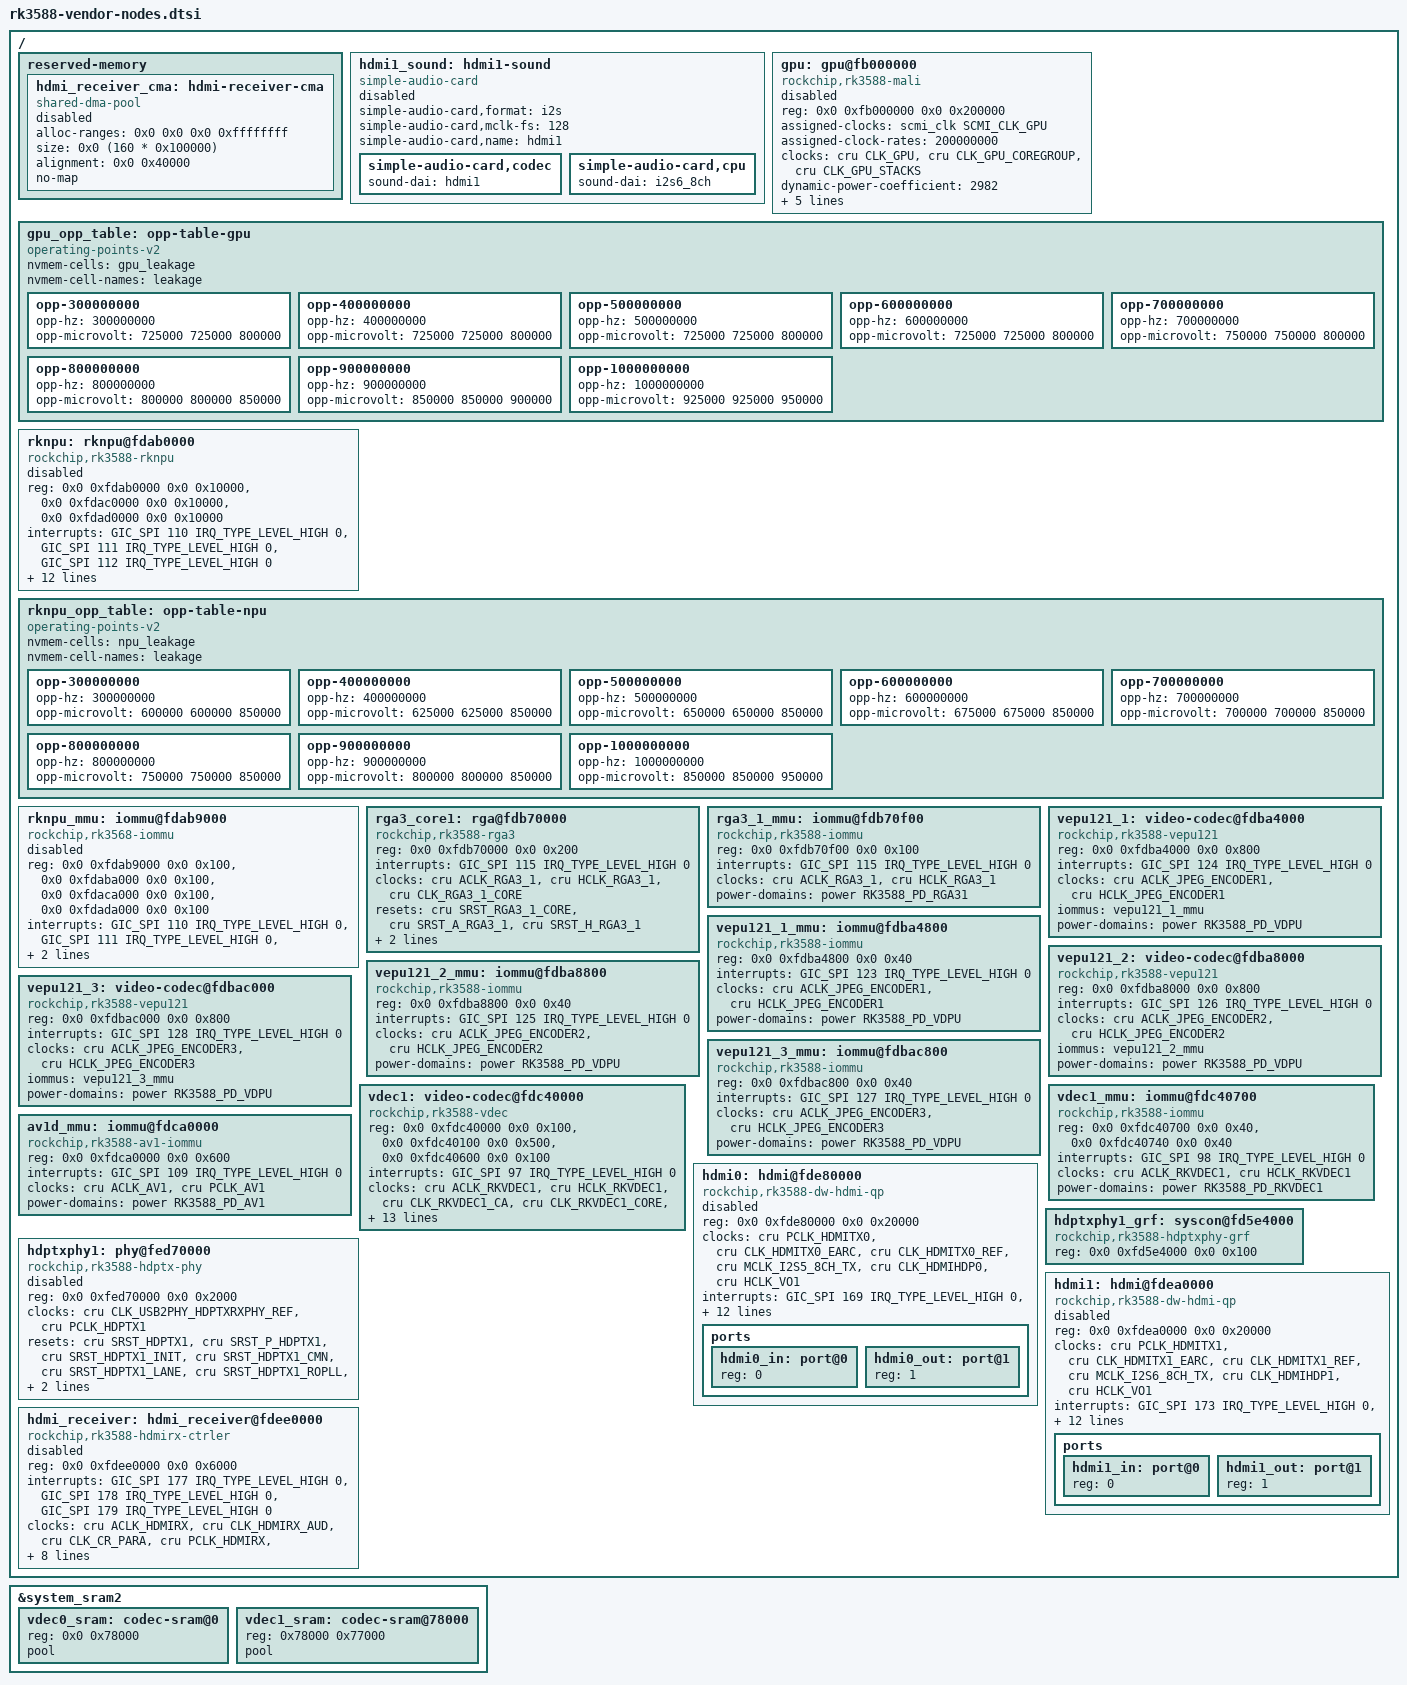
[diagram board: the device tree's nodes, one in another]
// SPDX-License-Identifier: (GPL-2.0+ OR MIT)
/*
 * RK3588 vendor SoC nodes missing from the mainline rk3588s.dtsi.
 *
 * The mainline rk3588s.dtsi (as used by the ophub 6.6 tree) lacks the
 * Rockchip vendor multimedia/IP nodes that the vendor BSP dtsi provides:
 * GPU (Mali), NPU (RKNN), RGA3, VPU/JPEG encoders (vepu121), video
 * decoder (vdec), HDMI TX controllers (hdmi0/hdmi1), HDMI PHY
 * (hdptxphy1), HDMI receiver, AV1 iommu, etc.
 *
 * This dtsi re-introduces those nodes (ported from the Rockchip 6.18
 * rk3588-base.dtsi / rk3588-extra.dtsi, which use the same mainline-style
 * compatible strings and #phy-cells conventions as this tree) so that
 * board DTS files written against the vendor node names can compile and
 * the corresponding drivers can bind.
 *
 * It is intended to be #included after "rk3588.dtsi" by board DTS files
 * that need these vendor nodes.  Boards that only use mainline nodes
 * (e.g. nanopc-t6, rock-5b) do not include it and are unaffected.
 *
 * Nodes already present in the mainline rk3588s.dtsi (vop, vp0-vp3,
 * display_subsystem, av1d, usbdp_phy0/1, usb_host*_xhci, u2phy*,
 * combphy*, hdptxphy_hdmi0, package_thermal, system_sram2, etc.) are
 * NOT redefined here.  Where a vendor node needs to reference one of
 * them, the existing label is used (e.g. hdmi0 phys = <&hdptxphy_hdmi0>).
 */

#include <dt-bindings/clock/rockchip,rk3588-cru.h>
#include <dt-bindings/interrupt-controller/arm-gic.h>
#include <dt-bindings/interrupt-controller/irq.h>
#include <dt-bindings/phy/phy.h>
#include <dt-bindings/power/rk3588-power.h>
#include <dt-bindings/reset/rockchip,rk3588-cru.h>
#include <dt-bindings/soc/rockchip,vop2.h>

/* The mainline reset header in this tree is missing this symbol. */
#ifndef SRST_A_HDMIRX_BIU
#define SRST_A_HDMIRX_BIU 660
#endif

/ {
	reserved-memory {
		#address-cells = <2>;
		#size-cells = <2>;
		ranges;

		hdmi_receiver_cma: hdmi-receiver-cma {
			compatible = "shared-dma-pool";
			alloc-ranges = <0x0 0x0 0x0 0xffffffff>;
			size = <0x0 (160 * 0x100000)>;
			alignment = <0x0 0x40000>;
			no-map;
			status = "disabled";
		};
	};

	hdmi1_sound: hdmi1-sound {
		compatible = "simple-audio-card";
		simple-audio-card,format = "i2s";
		simple-audio-card,mclk-fs = <128>;
		simple-audio-card,name = "hdmi1";
		status = "disabled";

		simple-audio-card,codec {
			sound-dai = <&hdmi1>;
		};

		simple-audio-card,cpu {
			sound-dai = <&i2s6_8ch>;
		};
	};

	gpu: gpu@fb000000 {
		compatible = "rockchip,rk3588-mali", "arm,mali-valhall-csf";
		reg = <0x0 0xfb000000 0x0 0x200000>;
		#cooling-cells = <2>;
		assigned-clocks = <&scmi_clk SCMI_CLK_GPU>;
		assigned-clock-rates = <200000000>;
		clocks = <&cru CLK_GPU>, <&cru CLK_GPU_COREGROUP>,
			 <&cru CLK_GPU_STACKS>;
		clock-names = "core", "coregroup", "stacks";
		dynamic-power-coefficient = <2982>;
		interrupts = <GIC_SPI 92 IRQ_TYPE_LEVEL_HIGH 0>,
			     <GIC_SPI 93 IRQ_TYPE_LEVEL_HIGH 0>,
			     <GIC_SPI 94 IRQ_TYPE_LEVEL_HIGH 0>;
		interrupt-names = "JOB", "MMU", "GPU";
		power-domains = <&power RK3588_PD_GPU>;
		operating-points-v2 = <&gpu_opp_table>;
		status = "disabled";
	};

	gpu_opp_table: opp-table-gpu {
		compatible = "operating-points-v2";
		nvmem-cells = <&gpu_leakage>;
		nvmem-cell-names = "leakage";

		opp-300000000 {
			opp-hz = /bits/ 64 <300000000>;
			opp-microvolt = <725000 725000 800000>;
		};

		opp-400000000 {
			opp-hz = /bits/ 64 <400000000>;
			opp-microvolt = <725000 725000 800000>;
		};

		opp-500000000 {
			opp-hz = /bits/ 64 <500000000>;
			opp-microvolt = <725000 725000 800000>;
		};

		opp-600000000 {
			opp-hz = /bits/ 64 <600000000>;
			opp-microvolt = <725000 725000 800000>;
		};

		opp-700000000 {
			opp-hz = /bits/ 64 <700000000>;
			opp-microvolt = <750000 750000 800000>;
		};

		opp-800000000 {
			opp-hz = /bits/ 64 <800000000>;
			opp-microvolt = <800000 800000 850000>;
		};

		opp-900000000 {
			opp-hz = /bits/ 64 <900000000>;
			opp-microvolt = <850000 850000 900000>;
		};

		opp-1000000000 {
			opp-hz = /bits/ 64 <1000000000>;
			opp-microvolt = <925000 925000 950000>;
		};
	};

	/*
	 * NPU (RKNN): single rknpu node managing all three cores, as
	 * expected by the Rockchip BSP rknpu driver
	 * (CONFIG_ROCKCHIP_RKNPU). The driver reads 3 reg regions and 3
	 * named interrupts ("npu0_irq".."npu2_irq") from this node.
	 * Ported from the Rockchip BSP rk3588-vendor-ip.dtsi.
	 */
	rknpu: rknpu@fdab0000 {
		compatible = "rockchip,rk3588-rknpu";
		reg = <0x0 0xfdab0000 0x0 0x10000>,
		      <0x0 0xfdac0000 0x0 0x10000>,
		      <0x0 0xfdad0000 0x0 0x10000>;
		interrupts = <GIC_SPI 110 IRQ_TYPE_LEVEL_HIGH 0>,
			     <GIC_SPI 111 IRQ_TYPE_LEVEL_HIGH 0>,
			     <GIC_SPI 112 IRQ_TYPE_LEVEL_HIGH 0>;
		interrupt-names = "npu0_irq", "npu1_irq", "npu2_irq";
		clocks = <&cru CLK_NPU_DSU0>, <&cru ACLK_NPU0>,
			 <&cru ACLK_NPU1>, <&cru ACLK_NPU2>,
			 <&cru HCLK_NPU0>, <&cru HCLK_NPU1>,
			 <&cru HCLK_NPU2>, <&cru PCLK_NPU_ROOT>;
		clock-names = "clk_npu", "aclk0", "aclk1", "aclk2",
			      "hclk0", "hclk1", "hclk2", "pclk";
		assigned-clocks = <&cru CLK_NPU_DSU0>;
		assigned-clock-rates = <200000000>;
		resets = <&cru SRST_A_RKNN0>, <&cru SRST_A_RKNN1>,
			 <&cru SRST_A_RKNN2>, <&cru SRST_H_RKNN0>,
			 <&cru SRST_H_RKNN1>, <&cru SRST_H_RKNN2>;
		reset-names = "srst_a0", "srst_a1", "srst_a2",
			      "srst_h0", "srst_h1", "srst_h2";
		power-domains = <&power RK3588_PD_NPUTOP>,
				<&power RK3588_PD_NPU1>,
				<&power RK3588_PD_NPU2>;
		power-domain-names = "npu0", "npu1", "npu2";
		operating-points-v2 = <&rknpu_opp_table>;
		status = "disabled";
	};

	rknpu_opp_table: opp-table-npu {
		compatible = "operating-points-v2";
		nvmem-cells = <&npu_leakage>;
		nvmem-cell-names = "leakage";

		opp-300000000 {
			opp-hz = /bits/ 64 <300000000>;
			opp-microvolt = <600000 600000 850000>;
		};

		opp-400000000 {
			opp-hz = /bits/ 64 <400000000>;
			opp-microvolt = <625000 625000 850000>;
		};

		opp-500000000 {
			opp-hz = /bits/ 64 <500000000>;
			opp-microvolt = <650000 650000 850000>;
		};

		opp-600000000 {
			opp-hz = /bits/ 64 <600000000>;
			opp-microvolt = <675000 675000 850000>;
		};

		opp-700000000 {
			opp-hz = /bits/ 64 <700000000>;
			opp-microvolt = <700000 700000 850000>;
		};

		opp-800000000 {
			opp-hz = /bits/ 64 <800000000>;
			opp-microvolt = <750000 750000 850000>;
		};

		opp-900000000 {
			opp-hz = /bits/ 64 <900000000>;
			opp-microvolt = <800000 800000 850000>;
		};

		opp-1000000000 {
			opp-hz = /bits/ 64 <1000000000>;
			opp-microvolt = <850000 850000 950000>;
		};
	};

	rknpu_mmu: iommu@fdab9000 {
		compatible = "rockchip,rk3568-iommu";
		reg = <0x0 0xfdab9000 0x0 0x100>,
		      <0x0 0xfdaba000 0x0 0x100>,
		      <0x0 0xfdaca000 0x0 0x100>,
		      <0x0 0xfdada000 0x0 0x100>;
		interrupts = <GIC_SPI 110 IRQ_TYPE_LEVEL_HIGH 0>,
			     <GIC_SPI 111 IRQ_TYPE_LEVEL_HIGH 0>,
			     <GIC_SPI 112 IRQ_TYPE_LEVEL_HIGH 0>;
		interrupt-names = "npu0_mmu", "npu1_mmu", "npu2_mmu";
		clocks = <&cru ACLK_NPU0>, <&cru HCLK_NPU0>;
		clock-names = "aclk", "iface";
		#iommu-cells = <0>;
		status = "disabled";
	};

	rga3_core1: rga@fdb70000 {
		compatible = "rockchip,rk3588-rga3";
		reg = <0x0 0xfdb70000 0x0 0x200>;
		interrupts = <GIC_SPI 115 IRQ_TYPE_LEVEL_HIGH 0>;
		clocks = <&cru ACLK_RGA3_1>, <&cru HCLK_RGA3_1>,
			 <&cru CLK_RGA3_1_CORE>;
		clock-names = "aclk", "hclk", "sclk";
		resets = <&cru SRST_RGA3_1_CORE>, <&cru SRST_A_RGA3_1>,
			 <&cru SRST_H_RGA3_1>;
		reset-names = "core", "axi", "ahb";
		power-domains = <&power RK3588_PD_RGA31>;
		iommus = <&rga3_1_mmu>;
	};

	rga3_1_mmu: iommu@fdb70f00 {
		compatible = "rockchip,rk3588-iommu", "rockchip,rk3568-iommu";
		reg = <0x0 0xfdb70f00 0x0 0x100>;
		interrupts = <GIC_SPI 115 IRQ_TYPE_LEVEL_HIGH 0>;
		clocks = <&cru ACLK_RGA3_1>, <&cru HCLK_RGA3_1>;
		clock-names = "aclk", "iface";
		#iommu-cells = <0>;
		power-domains = <&power RK3588_PD_RGA31>;
	};

	vepu121_1: video-codec@fdba4000 {
		compatible = "rockchip,rk3588-vepu121";
		reg = <0x0 0xfdba4000 0x0 0x800>;
		interrupts = <GIC_SPI 124 IRQ_TYPE_LEVEL_HIGH 0>;
		clocks = <&cru ACLK_JPEG_ENCODER1>, <&cru HCLK_JPEG_ENCODER1>;
		clock-names = "aclk", "hclk";
		iommus = <&vepu121_1_mmu>;
		power-domains = <&power RK3588_PD_VDPU>;
	};

	vepu121_1_mmu: iommu@fdba4800 {
		compatible = "rockchip,rk3588-iommu", "rockchip,rk3568-iommu";
		reg = <0x0 0xfdba4800 0x0 0x40>;
		interrupts = <GIC_SPI 123 IRQ_TYPE_LEVEL_HIGH 0>;
		clocks = <&cru ACLK_JPEG_ENCODER1>, <&cru HCLK_JPEG_ENCODER1>;
		clock-names = "aclk", "iface";
		power-domains = <&power RK3588_PD_VDPU>;
		#iommu-cells = <0>;
	};

	vepu121_2: video-codec@fdba8000 {
		compatible = "rockchip,rk3588-vepu121";
		reg = <0x0 0xfdba8000 0x0 0x800>;
		interrupts = <GIC_SPI 126 IRQ_TYPE_LEVEL_HIGH 0>;
		clocks = <&cru ACLK_JPEG_ENCODER2>, <&cru HCLK_JPEG_ENCODER2>;
		clock-names = "aclk", "hclk";
		iommus = <&vepu121_2_mmu>;
		power-domains = <&power RK3588_PD_VDPU>;
	};

	vepu121_2_mmu: iommu@fdba8800 {
		compatible = "rockchip,rk3588-iommu", "rockchip,rk3568-iommu";
		reg = <0x0 0xfdba8800 0x0 0x40>;
		interrupts = <GIC_SPI 125 IRQ_TYPE_LEVEL_HIGH 0>;
		clocks = <&cru ACLK_JPEG_ENCODER2>, <&cru HCLK_JPEG_ENCODER2>;
		clock-names = "aclk", "iface";
		power-domains = <&power RK3588_PD_VDPU>;
		#iommu-cells = <0>;
	};

	vepu121_3: video-codec@fdbac000 {
		compatible = "rockchip,rk3588-vepu121";
		reg = <0x0 0xfdbac000 0x0 0x800>;
		interrupts = <GIC_SPI 128 IRQ_TYPE_LEVEL_HIGH 0>;
		clocks = <&cru ACLK_JPEG_ENCODER3>, <&cru HCLK_JPEG_ENCODER3>;
		clock-names = "aclk", "hclk";
		iommus = <&vepu121_3_mmu>;
		power-domains = <&power RK3588_PD_VDPU>;
	};

	vepu121_3_mmu: iommu@fdbac800 {
		compatible = "rockchip,rk3588-iommu", "rockchip,rk3568-iommu";
		reg = <0x0 0xfdbac800 0x0 0x40>;
		interrupts = <GIC_SPI 127 IRQ_TYPE_LEVEL_HIGH 0>;
		clocks = <&cru ACLK_JPEG_ENCODER3>, <&cru HCLK_JPEG_ENCODER3>;
		clock-names = "aclk", "iface";
		power-domains = <&power RK3588_PD_VDPU>;
		#iommu-cells = <0>;
	};

	vdec1: video-codec@fdc40000 {
		compatible = "rockchip,rk3588-vdec";
		reg = <0x0 0xfdc40000 0x0 0x100>,
		      <0x0 0xfdc40100 0x0 0x500>,
		      <0x0 0xfdc40600 0x0 0x100>;
		reg-names = "link", "function", "cache";
		interrupts = <GIC_SPI 97 IRQ_TYPE_LEVEL_HIGH 0>;
		clocks = <&cru ACLK_RKVDEC1>, <&cru HCLK_RKVDEC1>,
			 <&cru CLK_RKVDEC1_CA>,
			 <&cru CLK_RKVDEC1_CORE>, <&cru CLK_RKVDEC1_HEVC_CA>;
		clock-names = "axi", "ahb", "cabac", "core", "hevc_cabac";
		assigned-clocks = <&cru ACLK_RKVDEC1>, <&cru CLK_RKVDEC1_CORE>,
				  <&cru CLK_RKVDEC1_CA>,
				  <&cru CLK_RKVDEC1_HEVC_CA>;
		assigned-clock-rates = <800000000>, <600000000>,
				       <600000000>, <1000000000>;
		iommus = <&vdec1_mmu>;
		power-domains = <&power RK3588_PD_RKVDEC1>;
		resets = <&cru SRST_A_RKVDEC1>, <&cru SRST_H_RKVDEC1>,
			 <&cru SRST_RKVDEC1_CA>,
			 <&cru SRST_RKVDEC1_CORE>, <&cru SRST_RKVDEC1_HEVC_CA>;
		reset-names = "axi", "ahb", "cabac", "core", "hevc_cabac";
		sram = <&vdec1_sram>;
	};

	vdec1_mmu: iommu@fdc40700 {
		compatible = "rockchip,rk3588-iommu", "rockchip,rk3568-iommu";
		reg = <0x0 0xfdc40700 0x0 0x40>, <0x0 0xfdc40740 0x0 0x40>;
		interrupts = <GIC_SPI 98 IRQ_TYPE_LEVEL_HIGH 0>;
		clocks = <&cru ACLK_RKVDEC1>, <&cru HCLK_RKVDEC1>;
		clock-names = "aclk", "iface";
		power-domains = <&power RK3588_PD_RKVDEC1>;
		#iommu-cells = <0>;
	};

	av1d_mmu: iommu@fdca0000 {
		compatible = "rockchip,rk3588-av1-iommu", "verisilicon,iommu-1.2";
		reg = <0x0 0xfdca0000 0x0 0x600>;
		interrupts = <GIC_SPI 109 IRQ_TYPE_LEVEL_HIGH 0>;
		clocks = <&cru ACLK_AV1>, <&cru PCLK_AV1>;
		clock-names = "core", "iface";
		#iommu-cells = <0>;
		power-domains = <&power RK3588_PD_AV1>;
	};

	hdmi0: hdmi@fde80000 {
		compatible = "rockchip,rk3588-dw-hdmi-qp";
		reg = <0x0 0xfde80000 0x0 0x20000>;
		clocks = <&cru PCLK_HDMITX0>,
			 <&cru CLK_HDMITX0_EARC>,
			 <&cru CLK_HDMITX0_REF>,
			 <&cru MCLK_I2S5_8CH_TX>,
			 <&cru CLK_HDMIHDP0>,
			 <&cru HCLK_VO1>;
		clock-names = "pclk", "earc", "ref", "aud", "hdp", "hclk_vo1";
		interrupts = <GIC_SPI 169 IRQ_TYPE_LEVEL_HIGH 0>,
			     <GIC_SPI 170 IRQ_TYPE_LEVEL_HIGH 0>,
			     <GIC_SPI 171 IRQ_TYPE_LEVEL_HIGH 0>,
			     <GIC_SPI 172 IRQ_TYPE_LEVEL_HIGH 0>,
			     <GIC_SPI 360 IRQ_TYPE_LEVEL_HIGH 0>;
		interrupt-names = "avp", "cec", "earc", "main", "hpd";
		phys = <&hdptxphy_hdmi0>;
		pinctrl-names = "default";
		pinctrl-0 = <&hdmim0_tx0_cec &hdmim0_tx0_hpd
			     &hdmim0_tx0_scl &hdmim0_tx0_sda>;
		power-domains = <&power RK3588_PD_VO1>;
		resets = <&cru SRST_HDMITX0_REF>, <&cru SRST_HDMIHDP0>;
		reset-names = "ref", "hdp";
		rockchip,grf = <&sys_grf>;
		rockchip,vo-grf = <&vo1_grf>;
		#sound-dai-cells = <0>;
		status = "disabled";

		ports {
			#address-cells = <1>;
			#size-cells = <0>;

			hdmi0_in: port@0 {
				reg = <0>;
			};

			hdmi0_out: port@1 {
				reg = <1>;
			};
		};
	};

	hdptxphy1_grf: syscon@fd5e4000 {
		compatible = "rockchip,rk3588-hdptxphy-grf", "syscon";
		reg = <0x0 0xfd5e4000 0x0 0x100>;
	};

	hdptxphy1: phy@fed70000 {
		compatible = "rockchip,rk3588-hdptx-phy";
		reg = <0x0 0xfed70000 0x0 0x2000>;
		clocks = <&cru CLK_USB2PHY_HDPTXRXPHY_REF>, <&cru PCLK_HDPTX1>;
		clock-names = "ref", "apb";
		#clock-cells = <0>;
		#phy-cells = <0>;
		resets = <&cru SRST_HDPTX1>, <&cru SRST_P_HDPTX1>,
			 <&cru SRST_HDPTX1_INIT>, <&cru SRST_HDPTX1_CMN>,
			 <&cru SRST_HDPTX1_LANE>, <&cru SRST_HDPTX1_ROPLL>,
			 <&cru SRST_HDPTX1_LCPLL>;
		reset-names = "phy", "apb", "init", "cmn", "lane", "ropll",
			      "lcpll";
		rockchip,grf = <&hdptxphy1_grf>;
		status = "disabled";
	};

	hdmi1: hdmi@fdea0000 {
		compatible = "rockchip,rk3588-dw-hdmi-qp";
		reg = <0x0 0xfdea0000 0x0 0x20000>;
		clocks = <&cru PCLK_HDMITX1>,
			 <&cru CLK_HDMITX1_EARC>,
			 <&cru CLK_HDMITX1_REF>,
			 <&cru MCLK_I2S6_8CH_TX>,
			 <&cru CLK_HDMIHDP1>,
			 <&cru HCLK_VO1>;
		clock-names = "pclk", "earc", "ref", "aud", "hdp", "hclk_vo1";
		interrupts = <GIC_SPI 173 IRQ_TYPE_LEVEL_HIGH 0>,
			     <GIC_SPI 174 IRQ_TYPE_LEVEL_HIGH 0>,
			     <GIC_SPI 175 IRQ_TYPE_LEVEL_HIGH 0>,
			     <GIC_SPI 176 IRQ_TYPE_LEVEL_HIGH 0>,
			     <GIC_SPI 361 IRQ_TYPE_LEVEL_HIGH 0>;
		interrupt-names = "avp", "cec", "earc", "main", "hpd";
		phys = <&hdptxphy1>;
		pinctrl-names = "default";
		pinctrl-0 = <&hdmim2_tx1_cec &hdmim0_tx1_hpd
			     &hdmim1_tx1_scl &hdmim1_tx1_sda>;
		power-domains = <&power RK3588_PD_VO1>;
		resets = <&cru SRST_HDMITX1_REF>, <&cru SRST_HDMIHDP1>;
		reset-names = "ref", "hdp";
		rockchip,grf = <&sys_grf>;
		rockchip,vo-grf = <&vo1_grf>;
		#sound-dai-cells = <0>;
		status = "disabled";

		ports {
			#address-cells = <1>;
			#size-cells = <0>;

			hdmi1_in: port@0 {
				reg = <0>;
			};

			hdmi1_out: port@1 {
				reg = <1>;
			};
		};
	};

	hdmi_receiver: hdmi_receiver@fdee0000 {
		compatible = "rockchip,rk3588-hdmirx-ctrler", "snps,dw-hdmi-rx";
		reg = <0x0 0xfdee0000 0x0 0x6000>;
		interrupts = <GIC_SPI 177 IRQ_TYPE_LEVEL_HIGH 0>,
			     <GIC_SPI 178 IRQ_TYPE_LEVEL_HIGH 0>,
			     <GIC_SPI 179 IRQ_TYPE_LEVEL_HIGH 0>;
		interrupt-names = "cec", "hdmi", "dma";
		clocks = <&cru ACLK_HDMIRX>,
			 <&cru CLK_HDMIRX_AUD>,
			 <&cru CLK_CR_PARA>,
			 <&cru PCLK_HDMIRX>,
			 <&cru CLK_HDMIRX_REF>,
			 <&cru PCLK_S_HDMIRX>,
			 <&cru HCLK_VO1>;
		clock-names = "aclk",
			      "audio",
			      "cr_para",
			      "pclk",
			      "ref",
			      "hclk_s_hdmirx",
			      "hclk_vo1";
		memory-region = <&hdmi_receiver_cma>;
		power-domains = <&power RK3588_PD_VO1>;
		resets = <&cru SRST_A_HDMIRX>, <&cru SRST_P_HDMIRX>,
			 <&cru SRST_HDMIRX_REF>, <&cru SRST_A_HDMIRX_BIU>;
		reset-names = "axi", "apb", "ref", "biu";
		rockchip,grf = <&sys_grf>;
		rockchip,vo1-grf = <&vo1_grf>;
		status = "disabled";
	};
};

/*
 * Codec SRAM pools for the video decoders.  The mainline rk3588s.dtsi
 * defines system_sram2 but does not carve out the per-codec pools that
 * the vdec nodes reference via sram = <&vdec*_sram>.
 */
&system_sram2 {
	vdec0_sram: codec-sram@0 {
		reg = <0x0 0x78000>;
		pool;
	};

	vdec1_sram: codec-sram@78000 {
		reg = <0x78000 0x77000>;
		pool;
	};
};
